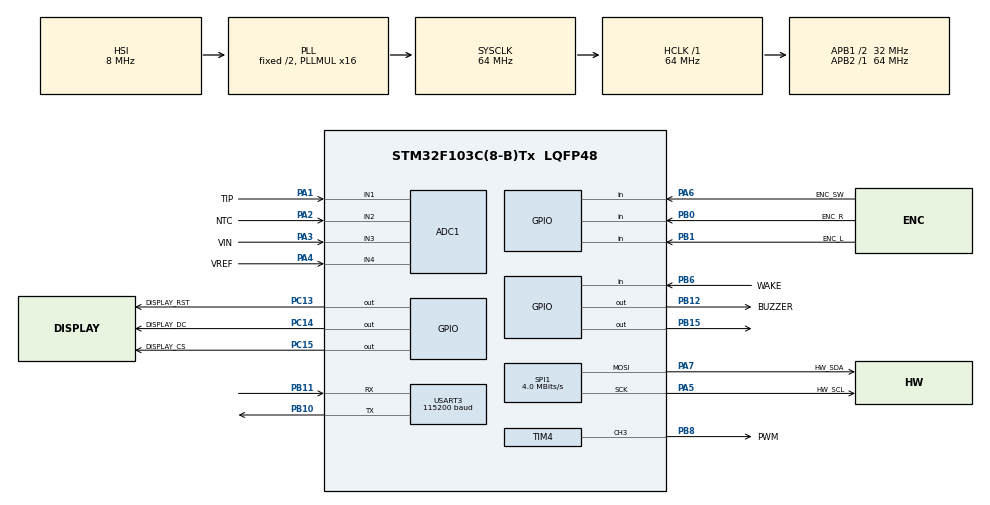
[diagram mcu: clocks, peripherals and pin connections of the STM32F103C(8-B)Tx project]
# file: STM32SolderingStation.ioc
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ADC1.Channel-0\#ChannelRegularConversion=ADC_CHANNEL_1
ADC1.Channel-1\#ChannelRegularConversion=ADC_CHANNEL_2
ADC1.Channel-2\#ChannelRegularConversion=ADC_CHANNEL_3
ADC1.ContinuousConvMode=ENABLE
ADC1.ExternalTrigConv=ADC_SOFTWARE_START
ADC1.NbrOfConversion=3
ADC1.NbrOfConversionFlag=1
ADC1.Rank-0\#ChannelRegularConversion=1
ADC1.Rank-1\#ChannelRegularConversion=2
ADC1.Rank-2\#ChannelRegularConversion=3
ADC1.SamplingTime-0\#ChannelRegularConversion=ADC_SAMPLETIME_13CYCLES_5
ADC1.SamplingTime-1\#ChannelRegularConversion=ADC_SAMPLETIME_13CYCLES_5
ADC1.SamplingTime-2\#ChannelRegularConversion=ADC_SAMPLETIME_13CYCLES_5
ADC1.master=1
Dma.ADC1.0.Direction=DMA_PERIPH_TO_MEMORY
Dma.ADC1.0.Instance=DMA1_Channel1
Dma.ADC1.0.MemDataAlignment=DMA_MDATAALIGN_HALFWORD
Dma.ADC1.0.MemInc=DMA_MINC_ENABLE
Dma.ADC1.0.Mode=DMA_NORMAL
Dma.ADC1.0.PeriphDataAlignment=DMA_PDATAALIGN_HALFWORD
Dma.ADC1.0.PeriphInc=DMA_PINC_DISABLE
Dma.ADC1.0.Priority=DMA_PRIORITY_VERY_HIGH
Dma.MEMTOMEM.1.Direction=DMA_MEMORY_TO_MEMORY
Dma.MEMTOMEM.1.Instance=DMA1_Channel2
Dma.MEMTOMEM.1.MemDataAlignment=DMA_MDATAALIGN_WORD
Dma.MEMTOMEM.1.MemInc=DMA_MINC_ENABLE
Dma.MEMTOMEM.1.Mode=DMA_NORMAL
Dma.MEMTOMEM.1.PeriphDataAlignment=DMA_PDATAALIGN_WORD
Dma.MEMTOMEM.1.PeriphInc=DMA_PINC_DISABLE
Dma.MEMTOMEM.1.Priority=DMA_PRIORITY_LOW
Dma.Request0=ADC1
Dma.Request1=MEMTOMEM
Dma.Request2=SPI1_TX
Dma.SPI1_TX.2.Direction=DMA_MEMORY_TO_PERIPH
Dma.SPI1_TX.2.Instance=DMA1_Channel3
Dma.SPI1_TX.2.MemDataAlignment=DMA_MDATAALIGN_BYTE
Dma.SPI1_TX.2.MemInc=DMA_MINC_ENABLE
Dma.SPI1_TX.2.Mode=DMA_NORMAL
Dma.SPI1_TX.2.PeriphDataAlignment=DMA_PDATAALIGN_BYTE
Dma.SPI1_TX.2.PeriphInc=DMA_PINC_DISABLE
Dma.SPI1_TX.2.Priority=DMA_PRIORITY_LOW
IWDG.Prescaler=IWDG_PRESCALER_32
IWDG.Reload=624
Mcu.Family=STM32F1
Mcu.Name=STM32F103C(8-B)Tx
Mcu.Package=LQFP48
NVIC.DMA1_Channel1_IRQn=true\:1\:0\:true\:false\:true\:false\:true\:true
NVIC.DMA1_Channel3_IRQn=true\:3\:0\:true\:false\:true\:false\:true\:true
NVIC.PriorityGroup=NVIC_PRIORITYGROUP_4
NVIC.TIM3_IRQn=true\:2\:0\:true\:false\:true\:true\:true\:true
PA1.GPIO_Label=TIP
PA1.Signal=ADCx_IN1
PA13.Mode=Serial_Wire
PA13.Signal=SYS_JTMS-SWDIO
PA14.Mode=Serial_Wire
PA14.Signal=SYS_JTCK-SWCLK
PA2.GPIO_Label=NTC
PA2.Signal=ADCx_IN2
PA3.GPIO_Label=VIN
PA3.Signal=ADCx_IN3
PA4.GPIO_Label=VREF
PA4.Signal=ADCx_IN4
PA5.GPIO_Label=HW_SCL
PA5.Mode=TX_Only_Simplex_Unidirect_Master
PA5.Signal=SPI1_SCK
PA6.GPIO_Label=ENC_SW
PA6.Signal=GPIO_Input
PA7.GPIO_Label=HW_SDA
PA7.Mode=TX_Only_Simplex_Unidirect_Master
PA7.Signal=SPI1_MOSI
PB0.GPIO_Label=ENC_R
PB0.Signal=GPIO_Input
PB1.GPIO_Label=ENC_L
PB1.Signal=GPIO_Input
PB10.Mode=Asynchronous
PB10.Signal=USART3_TX
PB11.Mode=Asynchronous
PB11.Signal=USART3_RX
PB12.GPIO_Label=BUZZER
PB12.Signal=GPIO_Output
PB15.Signal=GPIO_Output
PB6.GPIO_Label=WAKE
PB6.Signal=GPIO_Input
PB8.GPIO_Label=PWM
PB8.Signal=S_TIM4_CH3
PC13-TAMPER-RTC.GPIO_Label=DISPLAY_RST
PC13-TAMPER-RTC.Signal=GPIO_Output
PC14-OSC32_IN.GPIO_Label=DISPLAY_DC
PC14-OSC32_IN.Signal=GPIO_Output
PC15-OSC32_OUT.GPIO_Label=DISPLAY_CS
PC15-OSC32_OUT.Signal=GPIO_Output
ProjectManager.HeapSize=0xC00
ProjectManager.StackSize=0x400
ProjectManager.TargetToolchain=STM32CubeIDE
RCC.ADCPresc=RCC_ADCPCLK2_DIV6
RCC.AHBFreq_Value=64000000
RCC.APB1CLKDivider=RCC_HCLK_DIV2
RCC.APB1Freq_Value=32000000
RCC.APB1TimFreq_Value=64000000
RCC.APB2Freq_Value=64000000
RCC.APB2TimFreq_Value=64000000
RCC.HCLKFreq_Value=64000000
RCC.HSEDivPLL=RCC_HSE_PREDIV_DIV2
RCC.HSE_VALUE=16000000
RCC.PLLMUL=RCC_PLL_MUL16
RCC.SYSCLKFreq_VALUE=64000000
RCC.SYSCLKSource=RCC_SYSCLKSOURCE_PLLCLK
RCC.USBFreq_Value=64000000
SH.ADCx_IN1.0=ADC1_IN1,IN1
SH.ADCx_IN2.0=ADC1_IN2,IN2
SH.ADCx_IN3.0=ADC1_IN3,IN3
SH.ADCx_IN4.0=ADC1_IN4,IN4
SH.S_TIM4_CH3.0=TIM4_CH3,PWM Generation3 CH3
SPI1.BaudRatePrescaler=SPI_BAUDRATEPRESCALER_16
SPI1.CalculateBaudRate=4.0 MBits/s
SPI1.Direction=SPI_DIRECTION_2LINES
SPI1.Mode=SPI_MODE_MASTER
SPI1.VirtualType=VM_MASTER
TIM3.AutoReloadPreload=TIM_AUTORELOAD_PRELOAD_ENABLE
TIM3.Period=1999
TIM3.Prescaler=639
TIM3.TIM_MasterOutputTrigger=TIM_TRGO_UPDATE
TIM4.AutoReloadPreload=TIM_AUTORELOAD_PRELOAD_DISABLE
TIM4.Channel-PWM\ Generation3\ CH3=TIM_CHANNEL_3
TIM4.OC3Preload_PWM=DISABLE
TIM4.OCFastMode_PWM-PWM\ Generation3\ CH3=TIM_OCFAST_ENABLE
TIM4.Period=19999
TIM4.Prescaler=639
USART3.BaudRate=115200
USART3.VirtualMode=VM_ASYNC
VP_CRC_VS_CRC.Mode=CRC_Activate
VP_IWDG_VS_IWDG.Mode=IWDG_Activate
VP_TIM3_VS_ClockSourceINT.Mode=Internal
VP_TIM4_VS_ClockSourceINT.Mode=Internal
board=custom

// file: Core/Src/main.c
/* USER CODE BEGIN Header */
/**
  ******************************************************************************
  * @file           : main.c
  * @brief          : Main program body
  ******************************************************************************
  * @attention
  *
  * <h2><center>&copy; Copyright (c) 2020 STMicroelectronics.
  * All rights reserved.</center></h2>
  *
  * This software component is licensed by ST under BSD 3-Clause license,
  * the "License"; You may not use this file except in compliance with the
  * License. You may obtain a copy of the License at:
  *                        opensource.org/licenses/BSD-3-Clause
  *
  ******************************************************************************
  */
/* USER CODE END Header */
#include "main.h"

/* USER CODE BEGIN Includes */

#include "user_main.h"

/* USER CODE END Includes */

/* USER CODE BEGIN PD */
#ifdef __BASE_FILE__
#undef __BASE_FILE__
#define __BASE_FILE__ "main.c"
#endif
/* USER CODE END PD */

 ADC_HandleTypeDef hadc1;
DMA_HandleTypeDef hdma_adc1;

CRC_HandleTypeDef hcrc;

IWDG_HandleTypeDef hiwdg;

SPI_HandleTypeDef hspi1;
DMA_HandleTypeDef hdma_spi1_tx;

TIM_HandleTypeDef htim3;
TIM_HandleTypeDef htim4;

UART_HandleTypeDef huart3;

DMA_HandleTypeDef hdma_memtomem_dma1_channel2;

void SystemClock_Config(void);
static void MX_GPIO_Init(void);
static void MX_DMA_Init(void);
static void MX_TIM4_Init(void);
static void MX_TIM3_Init(void);
static void MX_ADC1_Init(void);
static void MX_CRC_Init(void);
static void MX_IWDG_Init(void);
static void MX_SPI1_Init(void);
static void MX_USART3_UART_Init(void);

int main(void)
{
  /* USER CODE BEGIN 1 */

  initBeforeMCUConfiguration();

  /* USER CODE END 1 */

  /* MCU Configuration--------------------------------------------------------*/

  /* Reset of all peripherals, Initializes the Flash interface and the Systick. */
  HAL_Init();

  /* Configure the system clock */
  SystemClock_Config();

  /* Initialize all configured peripherals */
  MX_GPIO_Init();
  MX_DMA_Init();
  MX_TIM4_Init();
  MX_TIM3_Init();
  MX_ADC1_Init();
  MX_CRC_Init();
  MX_IWDG_Init();
  MX_SPI1_Init();
  MX_USART3_UART_Init();
  /* USER CODE BEGIN 2 */
  InitAfterMCUConfiguration();
  /* USER CODE END 2 */

  /* Infinite loop */
  /* USER CODE BEGIN WHILE */
 // char txBuff[100]={0};
  while (1)
  {
    /* USER CODE END WHILE */

    /* USER CODE BEGIN 3 */
	mainCycle();
//	sprintf(txBuff,"%d\r\n",TIP.last_avg);
//	//strcpy(txBuff, "wolololo\r\n");
//	//sprintf(txBuff,"test\r\n");
//	HAL_UART_Transmit(&huart3, txBuff, strlen(txBuff)+1, 1000);
//	HAL_Delay(100);
  }
  /* USER CODE END 3 */
}

void SystemClock_Config(void)
{
  RCC_OscInitTypeDef RCC_OscInitStruct = {0};
  RCC_ClkInitTypeDef RCC_ClkInitStruct = {0};
  RCC_PeriphCLKInitTypeDef PeriphClkInit = {0};

  /** Initializes the RCC Oscillators according to the specified parameters
  * in the RCC_OscInitTypeDef structure.
  */
  RCC_OscInitStruct.OscillatorType = RCC_OSCILLATORTYPE_HSI|RCC_OSCILLATORTYPE_LSI;
  RCC_OscInitStruct.HSIState = RCC_HSI_ON;
  RCC_OscInitStruct.HSICalibrationValue = RCC_HSICALIBRATION_DEFAULT;
  RCC_OscInitStruct.LSIState = RCC_LSI_ON;
  RCC_OscInitStruct.PLL.PLLState = RCC_PLL_ON;
  RCC_OscInitStruct.PLL.PLLSource = RCC_PLLSOURCE_HSI_DIV2;
  RCC_OscInitStruct.PLL.PLLMUL = RCC_PLL_MUL16;
  if (HAL_RCC_OscConfig(&RCC_OscInitStruct) != HAL_OK)
  {
    Error_Handler();
  }

  /** Initializes the CPU, AHB and APB buses clocks
  */
  RCC_ClkInitStruct.ClockType = RCC_CLOCKTYPE_HCLK|RCC_CLOCKTYPE_SYSCLK
                              |RCC_CLOCKTYPE_PCLK1|RCC_CLOCKTYPE_PCLK2;
  RCC_ClkInitStruct.SYSCLKSource = RCC_SYSCLKSOURCE_PLLCLK;
  RCC_ClkInitStruct.AHBCLKDivider = RCC_SYSCLK_DIV1;
  RCC_ClkInitStruct.APB1CLKDivider = RCC_HCLK_DIV2;
  RCC_ClkInitStruct.APB2CLKDivider = RCC_HCLK_DIV1;

  if (HAL_RCC_ClockConfig(&RCC_ClkInitStruct, FLASH_LATENCY_2) != HAL_OK)
  {
    Error_Handler();
  }
  PeriphClkInit.PeriphClockSelection = RCC_PERIPHCLK_ADC;
  PeriphClkInit.AdcClockSelection = RCC_ADCPCLK2_DIV6;
  if (HAL_RCCEx_PeriphCLKConfig(&PeriphClkInit) != HAL_OK)
  {
    Error_Handler();
  }
}

static void MX_ADC1_Init(void)
{

  ADC_ChannelConfTypeDef sConfig = {0};

  /** Common config
  */
  hadc1.Instance = ADC1;
  hadc1.Init.ScanConvMode = ADC_SCAN_ENABLE;
  hadc1.Init.ContinuousConvMode = ENABLE;
  hadc1.Init.DiscontinuousConvMode = DISABLE;
  hadc1.Init.ExternalTrigConv = ADC_SOFTWARE_START;
  hadc1.Init.DataAlign = ADC_DATAALIGN_RIGHT;
  hadc1.Init.NbrOfConversion = 3;
  if (HAL_ADC_Init(&hadc1) != HAL_OK)
  {
    Error_Handler();
  }

  /** Configure Regular Channel
  */
  sConfig.Channel = ADC_CHANNEL_1;
  sConfig.Rank = ADC_REGULAR_RANK_1;
  sConfig.SamplingTime = ADC_SAMPLETIME_13CYCLES_5;
  if (HAL_ADC_ConfigChannel(&hadc1, &sConfig) != HAL_OK)
  {
    Error_Handler();
  }

  /** Configure Regular Channel
  */
  sConfig.Channel = ADC_CHANNEL_2;
  sConfig.Rank = ADC_REGULAR_RANK_2;
  if (HAL_ADC_ConfigChannel(&hadc1, &sConfig) != HAL_OK)
  {
    Error_Handler();
  }

  /** Configure Regular Channel
  */
  sConfig.Channel = ADC_CHANNEL_3;
  sConfig.Rank = ADC_REGULAR_RANK_3;
  if (HAL_ADC_ConfigChannel(&hadc1, &sConfig) != HAL_OK)
  {
    Error_Handler();
  }

}

static void MX_CRC_Init(void)
{

  hcrc.Instance = CRC;
  if (HAL_CRC_Init(&hcrc) != HAL_OK)
  {
    Error_Handler();
  }

}

static void MX_IWDG_Init(void)
{

  hiwdg.Instance = IWDG;
  hiwdg.Init.Prescaler = IWDG_PRESCALER_32;
  hiwdg.Init.Reload = 624;
  if (HAL_IWDG_Init(&hiwdg) != HAL_OK)
  {
    Error_Handler();
  }

}

static void MX_SPI1_Init(void)
{

  /* SPI1 parameter configuration*/
  hspi1.Instance = SPI1;
  hspi1.Init.Mode = SPI_MODE_MASTER;
  hspi1.Init.Direction = SPI_DIRECTION_2LINES;
  hspi1.Init.DataSize = SPI_DATASIZE_8BIT;
  hspi1.Init.CLKPolarity = SPI_POLARITY_LOW;
  hspi1.Init.CLKPhase = SPI_PHASE_1EDGE;
  hspi1.Init.NSS = SPI_NSS_SOFT;
  hspi1.Init.BaudRatePrescaler = SPI_BAUDRATEPRESCALER_16;
  hspi1.Init.FirstBit = SPI_FIRSTBIT_MSB;
  hspi1.Init.TIMode = SPI_TIMODE_DISABLE;
  hspi1.Init.CRCCalculation = SPI_CRCCALCULATION_DISABLE;
  hspi1.Init.CRCPolynomial = 10;
  if (HAL_SPI_Init(&hspi1) != HAL_OK)
  {
    Error_Handler();
  }

}

static void MX_TIM3_Init(void)
{

  TIM_ClockConfigTypeDef sClockSourceConfig = {0};
  TIM_MasterConfigTypeDef sMasterConfig = {0};

  htim3.Instance = TIM3;
  htim3.Init.Prescaler = 639;
  htim3.Init.CounterMode = TIM_COUNTERMODE_UP;
  htim3.Init.Period = 1999;
  htim3.Init.ClockDivision = TIM_CLOCKDIVISION_DIV1;
  htim3.Init.AutoReloadPreload = TIM_AUTORELOAD_PRELOAD_ENABLE;
  if (HAL_TIM_Base_Init(&htim3) != HAL_OK)
  {
    Error_Handler();
  }
  sClockSourceConfig.ClockSource = TIM_CLOCKSOURCE_INTERNAL;
  if (HAL_TIM_ConfigClockSource(&htim3, &sClockSourceConfig) != HAL_OK)
  {
    Error_Handler();
  }
  sMasterConfig.MasterOutputTrigger = TIM_TRGO_UPDATE;
  sMasterConfig.MasterSlaveMode = TIM_MASTERSLAVEMODE_DISABLE;
  if (HAL_TIMEx_MasterConfigSynchronization(&htim3, &sMasterConfig) != HAL_OK)
  {
    Error_Handler();
  }

}

static void MX_TIM4_Init(void)
{

  TIM_ClockConfigTypeDef sClockSourceConfig = {0};
  TIM_MasterConfigTypeDef sMasterConfig = {0};
  TIM_OC_InitTypeDef sConfigOC = {0};

  htim4.Instance = TIM4;
  htim4.Init.Prescaler = 639;
  htim4.Init.CounterMode = TIM_COUNTERMODE_UP;
  htim4.Init.Period = 19999;
  htim4.Init.ClockDivision = TIM_CLOCKDIVISION_DIV1;
  htim4.Init.AutoReloadPreload = TIM_AUTORELOAD_PRELOAD_DISABLE;
  if (HAL_TIM_Base_Init(&htim4) != HAL_OK)
  {
    Error_Handler();
  }
  sClockSourceConfig.ClockSource = TIM_CLOCKSOURCE_INTERNAL;
  if (HAL_TIM_ConfigClockSource(&htim4, &sClockSourceConfig) != HAL_OK)
  {
    Error_Handler();
  }
  if (HAL_TIM_PWM_Init(&htim4) != HAL_OK)
  {
    Error_Handler();
  }
  sMasterConfig.MasterOutputTrigger = TIM_TRGO_RESET;
  sMasterConfig.MasterSlaveMode = TIM_MASTERSLAVEMODE_DISABLE;
  if (HAL_TIMEx_MasterConfigSynchronization(&htim4, &sMasterConfig) != HAL_OK)
  {
    Error_Handler();
  }
  sConfigOC.OCMode = TIM_OCMODE_PWM1;
  sConfigOC.Pulse = 0;
  sConfigOC.OCPolarity = TIM_OCPOLARITY_HIGH;
  sConfigOC.OCFastMode = TIM_OCFAST_ENABLE;
  if (HAL_TIM_PWM_ConfigChannel(&htim4, &sConfigOC, TIM_CHANNEL_3) != HAL_OK)
  {
    Error_Handler();
  }
  __HAL_TIM_DISABLE_OCxPRELOAD(&htim4, TIM_CHANNEL_3);
  HAL_TIM_MspPostInit(&htim4);

}

static void MX_USART3_UART_Init(void)
{

  huart3.Instance = USART3;
  huart3.Init.BaudRate = 115200;
  huart3.Init.WordLength = UART_WORDLENGTH_8B;
  huart3.Init.StopBits = UART_STOPBITS_1;
  huart3.Init.Parity = UART_PARITY_NONE;
  huart3.Init.Mode = UART_MODE_TX_RX;
  huart3.Init.HwFlowCtl = UART_HWCONTROL_NONE;
  huart3.Init.OverSampling = UART_OVERSAMPLING_16;
  if (HAL_UART_Init(&huart3) != HAL_OK)
  {
    Error_Handler();
  }

}

static void MX_DMA_Init(void)
{

  /* DMA controller clock enable */
  __HAL_RCC_DMA1_CLK_ENABLE();

  /* Configure DMA request hdma_memtomem_dma1_channel2 on DMA1_Channel2 */
  hdma_memtomem_dma1_channel2.Instance = DMA1_Channel2;
  hdma_memtomem_dma1_channel2.Init.Direction = DMA_MEMORY_TO_MEMORY;
  hdma_memtomem_dma1_channel2.Init.PeriphInc = DMA_PINC_DISABLE;
  hdma_memtomem_dma1_channel2.Init.MemInc = DMA_MINC_ENABLE;
  hdma_memtomem_dma1_channel2.Init.PeriphDataAlignment = DMA_PDATAALIGN_WORD;
  hdma_memtomem_dma1_channel2.Init.MemDataAlignment = DMA_MDATAALIGN_WORD;
  hdma_memtomem_dma1_channel2.Init.Mode = DMA_NORMAL;
  hdma_memtomem_dma1_channel2.Init.Priority = DMA_PRIORITY_LOW;
  if (HAL_DMA_Init(&hdma_memtomem_dma1_channel2) != HAL_OK)
  {
    Error_Handler( );
  }

  /* DMA interrupt init */
  /* DMA1_Channel1_IRQn interrupt configuration */
  HAL_NVIC_SetPriority(DMA1_Channel1_IRQn, 1, 0);
  HAL_NVIC_EnableIRQ(DMA1_Channel1_IRQn);
  /* DMA1_Channel3_IRQn interrupt configuration */
  HAL_NVIC_SetPriority(DMA1_Channel3_IRQn, 3, 0);
  HAL_NVIC_EnableIRQ(DMA1_Channel3_IRQn);

}

static void MX_GPIO_Init(void)
{
  GPIO_InitTypeDef GPIO_InitStruct = {0};

  /* GPIO Ports Clock Enable */
  __HAL_RCC_GPIOC_CLK_ENABLE();
  __HAL_RCC_GPIOA_CLK_ENABLE();
  __HAL_RCC_GPIOB_CLK_ENABLE();

  /*Configure GPIO pin Output Level */
  HAL_GPIO_WritePin(GPIOC, DISPLAY_RST_Pin|DISPLAY_DC_Pin|DISPLAY_CS_Pin, GPIO_PIN_RESET);

  /*Configure GPIO pin Output Level */
  HAL_GPIO_WritePin(GPIOB, BUZZER_Pin|GPIO_PIN_15, GPIO_PIN_RESET);

  /*Configure GPIO pins : DISPLAY_RST_Pin DISPLAY_DC_Pin DISPLAY_CS_Pin */
  GPIO_InitStruct.Pin = DISPLAY_RST_Pin|DISPLAY_DC_Pin|DISPLAY_CS_Pin;
  GPIO_InitStruct.Mode = GPIO_MODE_OUTPUT_PP;
  GPIO_InitStruct.Pull = GPIO_NOPULL;
  GPIO_InitStruct.Speed = GPIO_SPEED_FREQ_LOW;
  HAL_GPIO_Init(GPIOC, &GPIO_InitStruct);

  /*Configure GPIO pin : ENC_SW_Pin */
  GPIO_InitStruct.Pin = ENC_SW_Pin;
  GPIO_InitStruct.Mode = GPIO_MODE_INPUT;
  GPIO_InitStruct.Pull = GPIO_NOPULL;
  HAL_GPIO_Init(ENC_SW_GPIO_Port, &GPIO_InitStruct);

  /*Configure GPIO pins : ENC_R_Pin ENC_L_Pin WAKE_Pin */
  GPIO_InitStruct.Pin = ENC_R_Pin|ENC_L_Pin|WAKE_Pin;
  GPIO_InitStruct.Mode = GPIO_MODE_INPUT;
  GPIO_InitStruct.Pull = GPIO_NOPULL;
  HAL_GPIO_Init(GPIOB, &GPIO_InitStruct);

  /*Configure GPIO pins : BUZZER_Pin PB15 */
  GPIO_InitStruct.Pin = BUZZER_Pin|GPIO_PIN_15;
  GPIO_InitStruct.Mode = GPIO_MODE_OUTPUT_PP;
  GPIO_InitStruct.Pull = GPIO_NOPULL;
  GPIO_InitStruct.Speed = GPIO_SPEED_FREQ_LOW;
  HAL_GPIO_Init(GPIOB, &GPIO_InitStruct);

}

void Error_Handler(void)
{
  /* USER CODE BEGIN Error_Handler_Debug */
  CrashErrorHandler(file, line);
  /* USER CODE END Error_Handler_Debug */
}
